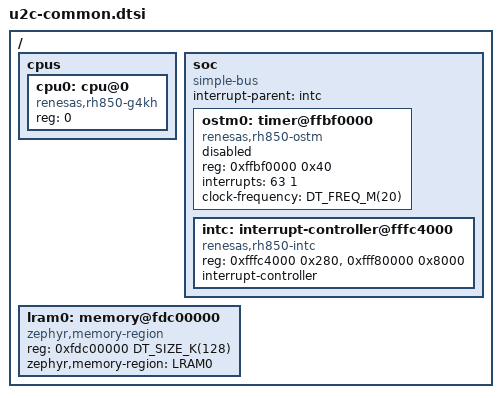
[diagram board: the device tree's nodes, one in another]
/*
 * SPDX-FileCopyrightText: Copyright (c) 2026 Linumiz
 *
 * SPDX-License-Identifier: Apache-2.0
 */

#include <freq.h>
#include <mem.h>
#include <skeleton.dtsi>

/ {
	cpus {
		#address-cells = <1>;
		#size-cells = <0>;

		cpu0: cpu@0 {
			compatible = "renesas,rh850-g4kh", "renesas,rh850";
			reg = <0>;
		};
	};

	soc {
		compatible = "simple-bus";
		ranges;
		#address-cells = <1>;
		#size-cells = <1>;
		interrupt-parent = <&intc>;

		ostm0: timer@ffbf0000 {
			compatible = "renesas,rh850-ostm";
			reg = <0xffbf0000 0x40>;
			interrupts = <63 1>;
			clock-frequency = <DT_FREQ_M(20)>;
			status = "disabled";
		};

		intc: interrupt-controller@fffc4000 {
			compatible = "renesas,rh850-intc";
			reg = <0xfffc4000 0x280>, <0xfff80000 0x8000>;
			reg-names = "intc1", "intc2";
			#address-cells = <0>;
			#interrupt-cells = <2>;
			interrupt-controller;
		};
	};

	lram0: memory@fdc00000 {
		compatible = "zephyr,memory-region", "mmio-sram";
		reg = <0xfdc00000 DT_SIZE_K(128)>;
		zephyr,memory-region = "LRAM0";
	};
};
